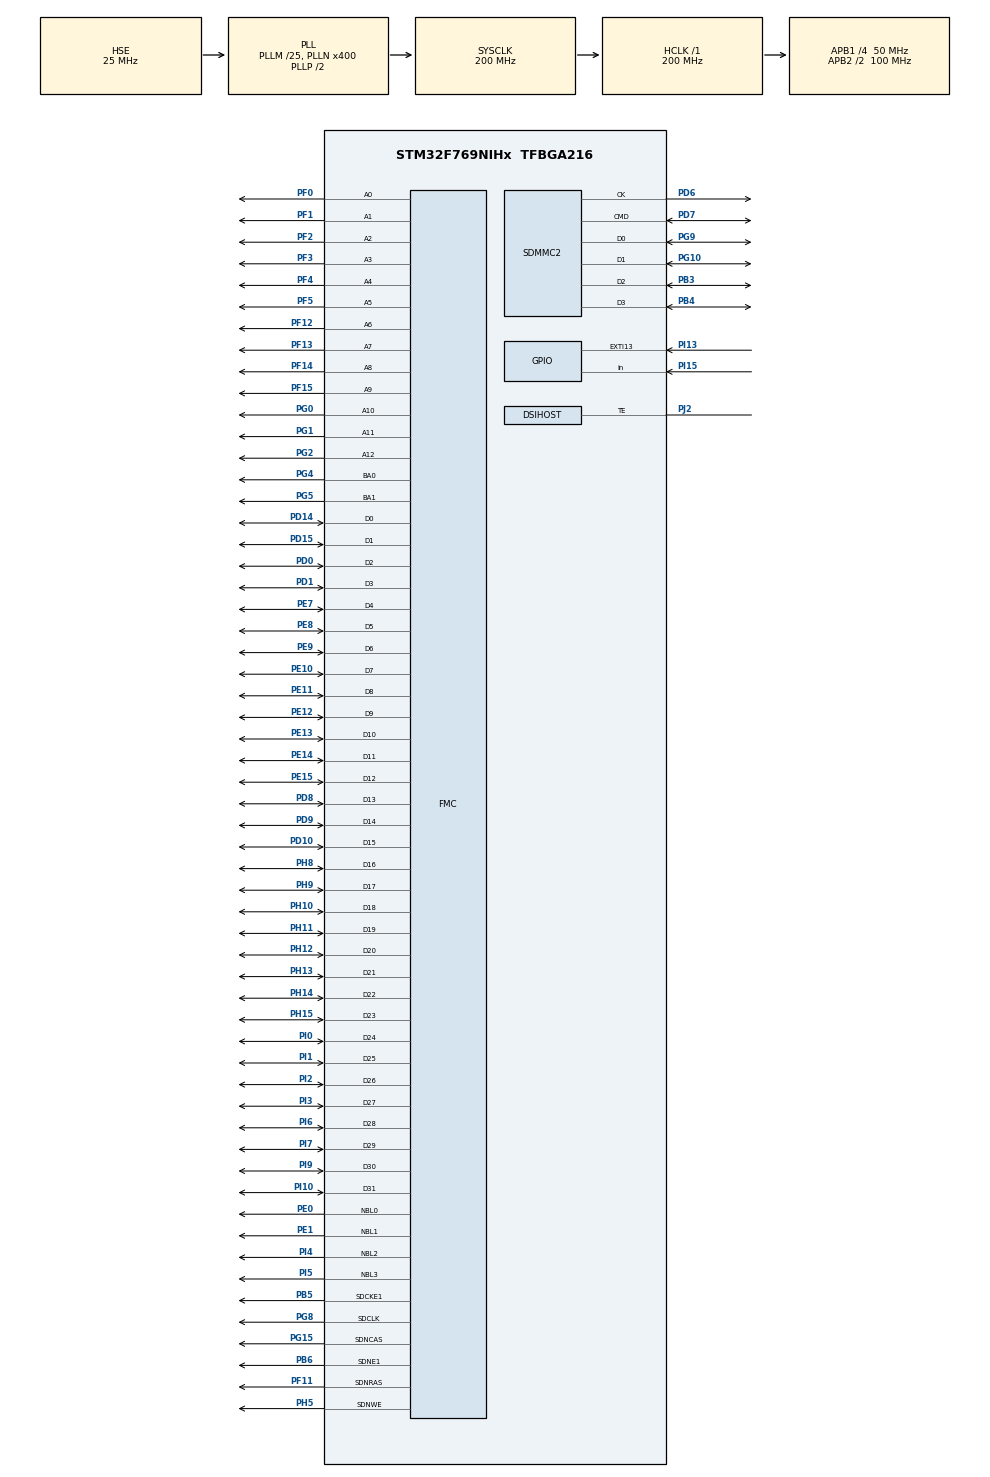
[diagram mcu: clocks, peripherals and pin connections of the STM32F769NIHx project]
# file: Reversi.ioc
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ADC1.Channel-0\#ChannelRegularConversion=ADC_CHANNEL_TEMPSENSOR
ADC1.NbrOfConversionFlag=1
ADC1.Rank-0\#ChannelRegularConversion=1
ADC1.SamplingTime-0\#ChannelRegularConversion=ADC_SAMPLETIME_3CYCLES
ADC1.master=1
CORTEX_M7.CPU_DCache=Enabled
CORTEX_M7.CPU_ICache=Enabled
DSIHOST_CKN.Mode=DSIHost_Adapted_TE
DSIHOST_CKN.Signal=DSIHOST_CKN
DSIHOST_CKP.Mode=DSIHost_Adapted_TE
DSIHOST_CKP.Signal=DSIHOST_CKP
DSIHOST_D0N.Mode=DSIHost_Adapted_TE
DSIHOST_D0N.Signal=DSIHOST_D0N
DSIHOST_D0P.Mode=DSIHost_Adapted_TE
DSIHOST_D0P.Signal=DSIHOST_D0P
DSIHOST_D1N.Mode=DSIHost_Adapted_TE
DSIHOST_D1N.Signal=DSIHOST_D1N
DSIHOST_D1P.Mode=DSIHost_Adapted_TE
DSIHOST_D1P.Signal=DSIHOST_D1P
FATFS.BSP.number=1
FATFS0.BSP.STBoard=false
FATFS0.BSP.api=Unknown
FATFS0.BSP.i2caddr=0
FATFS0.BSP.instance=PI15
FATFS0.BSP.ip=GPIO
FATFS0.BSP.mode=Input
FATFS0.BSP.name=Detect_SDIO
FATFS0.BSP.solution=PI15
Mcu.Family=STM32F7
Mcu.Name=STM32F769NIHx
Mcu.Package=TFBGA216
NVIC.ADC_IRQn=true\:0\:0\:false\:false\:true\:true\:true
NVIC.EXTI15_10_IRQn=true\:0\:0\:false\:false\:true\:true\:true
NVIC.PriorityGroup=NVIC_PRIORITYGROUP_4
NVIC.TIM6_DAC_IRQn=true\:0\:0\:false\:false\:true\:true\:true
NVIC.TIM7_IRQn=true\:0\:0\:false\:false\:true\:true\:true
PB3.Mode=SD_4_bits_Wide_bus
PB3.Signal=SDMMC2_D2
PB4.Mode=SD_4_bits_Wide_bus
PB4.Signal=SDMMC2_D3
PB5.Mode=SdramChipSelect2_1
PB5.Signal=FMC_SDCKE1
PB6.Mode=SdramChipSelect2_1
PB6.Signal=FMC_SDNE1
PD0.Signal=FMC_D2_DA2
PD1.Signal=FMC_D3_DA3
PD10.Signal=FMC_D15_DA15
PD14.Signal=FMC_D0_DA0
PD15.Signal=FMC_D1_DA1
PD6.Mode=SD_4_bits_Wide_bus
PD6.Signal=SDMMC2_CK
PD7.Mode=SD_4_bits_Wide_bus
PD7.Signal=SDMMC2_CMD
PD8.Signal=FMC_D13_DA13
PD9.Signal=FMC_D14_DA14
PE0.Signal=FMC_NBL0
PE1.Signal=FMC_NBL1
PE10.Signal=FMC_D7_DA7
PE11.Signal=FMC_D8_DA8
PE12.Signal=FMC_D9_DA9
PE13.Signal=FMC_D10_DA10
PE14.Signal=FMC_D11_DA11
PE15.Signal=FMC_D12_DA12
PE7.Signal=FMC_D4_DA4
PE8.Signal=FMC_D5_DA5
PE9.Signal=FMC_D6_DA6
PF0.Signal=FMC_A0
PF1.Signal=FMC_A1
PF11.Signal=FMC_SDNRAS
PF12.Signal=FMC_A6
PF13.Signal=FMC_A7
PF14.Signal=FMC_A8
PF15.Signal=FMC_A9
PF2.Signal=FMC_A2
PF3.Signal=FMC_A3
PF4.Signal=FMC_A4
PF5.Signal=FMC_A5
PG0.Signal=FMC_A10
PG1.Signal=FMC_A11
PG10.Mode=SD_4_bits_Wide_bus
PG10.Signal=SDMMC2_D1
PG15.Signal=FMC_SDNCAS
PG2.Signal=FMC_A12
PG4.Signal=FMC_A14_BA0
PG5.Signal=FMC_A15_BA1
PG8.Signal=FMC_SDCLK
PG9.Mode=SD_4_bits_Wide_bus
PG9.Signal=SDMMC2_D0
PH0/OSC_IN.Mode=HSE-External-Oscillator
PH0/OSC_IN.Signal=RCC_OSC_IN
PH1/OSC_OUT.Mode=HSE-External-Oscillator
PH1/OSC_OUT.Signal=RCC_OSC_OUT
PH10.Signal=FMC_D18
PH11.Signal=FMC_D19
PH12.Signal=FMC_D20
PH13.Signal=FMC_D21
PH14.Signal=FMC_D22
PH15.Signal=FMC_D23
PH5.Signal=FMC_SDNWE
PH8.Signal=FMC_D16
PH9.Signal=FMC_D17
PI0.Signal=FMC_D24
PI1.Signal=FMC_D25
PI10.Signal=FMC_D31
PI13.Signal=GPXTI13
PI15.Signal=GPIO_Input
PI2.Signal=FMC_D26
PI3.Signal=FMC_D27
PI4.Signal=FMC_NBL2
PI5.Signal=FMC_NBL3
PI6.Signal=FMC_D28
PI7.Signal=FMC_D29
PI9.Signal=FMC_D30
PJ2.Mode=DSIHost_Adapted_TE
PJ2.Signal=DSIHOST_TE
ProjectManager.HeapSize=0x200
ProjectManager.StackSize=0x400
ProjectManager.TargetToolchain=STM32CubeIDE
RCC.AHBFreq_Value=200000000
RCC.APB1CLKDivider=RCC_HCLK_DIV4
RCC.APB1Freq_Value=50000000
RCC.APB1TimFreq_Value=100000000
RCC.APB2CLKDivider=RCC_HCLK_DIV2
RCC.APB2Freq_Value=100000000
RCC.APB2TimFreq_Value=200000000
RCC.CortexFreq_Value=200000000
RCC.HCLKFreq_Value=200000000
RCC.HSE_VALUE=25000000
RCC.HSI_VALUE=16000000
RCC.LSE_VALUE=32768
RCC.PLLI2SN=96
RCC.PLLM=25
RCC.PLLN=400
RCC.PLLQ=8
RCC.PLLSourceVirtual=RCC_PLLSOURCE_HSE
RCC.SDMMC2ClockSelection=RCC_SDMMC2CLKSOURCE_CLK48
RCC.SYSCLKFreq_VALUE=200000000
RCC.SYSCLKSource=RCC_SYSCLKSOURCE_PLLCLK
RCC.USBFreq_Value=50000000
RCC.VCOOutputFreq_Value=400000000
SH.FMC_A0.0=FMC_A0,13b-sda1
SH.FMC_A1.0=FMC_A1,13b-sda1
SH.FMC_A10.0=FMC_A10,13b-sda1
SH.FMC_A11.0=FMC_A11,13b-sda1
SH.FMC_A12.0=FMC_A12,13b-sda1
SH.FMC_A14_BA0.0=FMC_BA0,FourSdramBanks1
SH.FMC_A15_BA1.0=FMC_BA1,FourSdramBanks1
SH.FMC_A2.0=FMC_A2,13b-sda1
SH.FMC_A3.0=FMC_A3,13b-sda1
SH.FMC_A4.0=FMC_A4,13b-sda1
SH.FMC_A5.0=FMC_A5,13b-sda1
SH.FMC_A6.0=FMC_A6,13b-sda1
SH.FMC_A7.0=FMC_A7,13b-sda1
SH.FMC_A8.0=FMC_A8,13b-sda1
SH.FMC_A9.0=FMC_A9,13b-sda1
SH.FMC_D0_DA0.0=FMC_D0,sd-32b-d1
SH.FMC_D10_DA10.0=FMC_D10,sd-32b-d1
SH.FMC_D11_DA11.0=FMC_D11,sd-32b-d1
SH.FMC_D12_DA12.0=FMC_D12,sd-32b-d1
SH.FMC_D13_DA13.0=FMC_D13,sd-32b-d1
SH.FMC_D14_DA14.0=FMC_D14,sd-32b-d1
SH.FMC_D15_DA15.0=FMC_D15,sd-32b-d1
SH.FMC_D16.0=FMC_D16,sd-32b-d1
SH.FMC_D17.0=FMC_D17,sd-32b-d1
SH.FMC_D18.0=FMC_D18,sd-32b-d1
SH.FMC_D19.0=FMC_D19,sd-32b-d1
SH.FMC_D1_DA1.0=FMC_D1,sd-32b-d1
SH.FMC_D20.0=FMC_D20,sd-32b-d1
SH.FMC_D21.0=FMC_D21,sd-32b-d1
SH.FMC_D22.0=FMC_D22,sd-32b-d1
SH.FMC_D23.0=FMC_D23,sd-32b-d1
SH.FMC_D24.0=FMC_D24,sd-32b-d1
SH.FMC_D25.0=FMC_D25,sd-32b-d1
SH.FMC_D26.0=FMC_D26,sd-32b-d1
SH.FMC_D27.0=FMC_D27,sd-32b-d1
SH.FMC_D28.0=FMC_D28,sd-32b-d1
SH.FMC_D29.0=FMC_D29,sd-32b-d1
SH.FMC_D2_DA2.0=FMC_D2,sd-32b-d1
SH.FMC_D30.0=FMC_D30,sd-32b-d1
SH.FMC_D31.0=FMC_D31,sd-32b-d1
SH.FMC_D3_DA3.0=FMC_D3,sd-32b-d1
SH.FMC_D4_DA4.0=FMC_D4,sd-32b-d1
SH.FMC_D5_DA5.0=FMC_D5,sd-32b-d1
SH.FMC_D6_DA6.0=FMC_D6,sd-32b-d1
SH.FMC_D7_DA7.0=FMC_D7,sd-32b-d1
SH.FMC_D8_DA8.0=FMC_D8,sd-32b-d1
SH.FMC_D9_DA9.0=FMC_D9,sd-32b-d1
SH.FMC_NBL0.0=FMC_NBL0,Sd4ByteEnable1
SH.FMC_NBL1.0=FMC_NBL1,Sd4ByteEnable1
SH.FMC_NBL2.0=FMC_NBL2,Sd4ByteEnable1
SH.FMC_NBL3.0=FMC_NBL3,Sd4ByteEnable1
SH.FMC_SDCLK.0=FMC_SDCLK,13b-sda1
SH.FMC_SDNCAS.0=FMC_SDNCAS,13b-sda1
SH.FMC_SDNRAS.0=FMC_SDNRAS,13b-sda1
SH.FMC_SDNWE.0=FMC_SDNWE,13b-sda1
TIM6.AutoReloadPreload=TIM_AUTORELOAD_PRELOAD_ENABLE
TIM6.Period=14141
TIM6.Prescaler=14141
TIM7.AutoReloadPreload=TIM_AUTORELOAD_PRELOAD_ENABLE
TIM7.Period=9999
TIM7.Prescaler=9999
VP_ADC1_TempSens_Input.Mode=IN-TempSens
VP_DMA2D_VS_DMA2D.Mode=DMA2D_Activate
VP_FATFS_VS_SDIO.Mode=SDIO
VP_LTDC_DSIMode.Mode=RGB888
VP_TIM6_VS_ClockSourceINT.Mode=Enable_Timer
VP_TIM7_VS_ClockSourceINT.Mode=Enable_Timer
board=STM32F769I-DISC1

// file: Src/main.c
/* USER CODE BEGIN Header */
/**
  ******************************************************************************
  * @file           : main.c
  * @brief          : Main program body
  ******************************************************************************
  * @attention
  *
  * <h2><center>&copy; Copyright (c) 2019 STMicroelectronics.
  * All rights reserved.</center></h2>
  *
  * This software component is licensed by ST under BSD 3-Clause license,
  * the "License"; You may not use this file except in compliance with the
  * License. You may obtain a copy of the License at:
  *                        opensource.org/licenses/BSD-3-Clause
  *
  ******************************************************************************
  */
/* USER CODE END Header */

#include "main.h"
#include "fatfs.h"

/* USER CODE BEGIN Includes */
#include "stm32f769i_discovery.h"
#include "stm32f769i_discovery_lcd.h"
#include "stm32f769i_discovery_ts.h"
#include "stdio.h"
#include <stdlib.h>
#include <time.h>
/* USER CODE END Includes */

/* USER CODE BEGIN PD */
#define TEMP_REFRESH_PERIOD   1000    /* Internal temperature refresh period */
#define MAX_CONVERTED_VALUE   4095    /* Max converted value */
#define AMBIENT_TEMP            25    /* Ambient Temperature */
#define VSENS_AT_AMBIENT_TEMP  760    /* VSENSE value (mv) at ambient temperature */
#define AVG_SLOPE               25    /* Avg_Solpe multiply by 10 */
#define VREF                  3300
/* USER CODE END PD */

ADC_HandleTypeDef hadc1;

DMA2D_HandleTypeDef hdma2d;

DSI_HandleTypeDef hdsi;

LTDC_HandleTypeDef hltdc;

SD_HandleTypeDef hsd2;

TIM_HandleTypeDef htim6;
TIM_HandleTypeDef htim7;

SDRAM_HandleTypeDef hsdram1;

/* USER CODE BEGIN PV */

 int flagTemp=0;
TS_StateTypeDef TS_State;
uint32_t ConvertedValue;
long int JTemp;
char desc[100];
char clockTime[20];
char timerString[20];
char timeOutString[20];

int flagTouchScreen=0;
int startSoft=0;
int startARMSoft=0;

int sec=0;
int min=0;
int hour=0;

int turnFlag=0;
int startFlag=0;
int startARMFlag=0;
int flagClock=0;
int downTimer=20;

char board[8][8]={"........",
                  "........",
                  "........",
                  "...xo...",
                  "...ox...",
                  "........",
                  "........",
                  "........"};

char symbPlayer;
char symbAdv;

int newPlayer=0;
int gameON=0;
int gameARMon=0;
int gameEnd=0;
int firstMove=0;

uint16_t casaX=0;
uint16_t casaY=0;
uint16_t jogadaX=0;
uint16_t jogadaY=0;

uint32_t colorP1 =  LCD_COLOR_LIGHTGREEN ;
uint32_t colorP2 =  LCD_COLOR_LIGHTRED ;
uint32_t colorPlayer;
//uint32_t colorAdv;

int timOutFlag=0;
int timOutP1=0;
int timOutP2=0;

int j=0;
int k=0;
int l=0;

int jogPossiveisX[20]={0};
int jogPossiveisY[20]={0};
int indx=0;

/* USER CODE END PV */

void SystemClock_Config(void);
static void MX_GPIO_Init(void);
static void MX_ADC1_Init(void);
static void MX_DMA2D_Init(void);
static void MX_DSIHOST_DSI_Init(void);
static void MX_FMC_Init(void);
static void MX_LTDC_Init(void);
static void MX_SDMMC2_SD_Init(void);
static void MX_TIM6_Init(void);
static void MX_TIM7_Init(void);
/* USER CODE BEGIN PFP */

static void LCD_Config();

static void startGame();

void gameOver();

void playARM();

void playHuman();

void jogadasPossiveis(char symbPlayer, char symbAdv);

void jogada(char symbPlayer, char symbAdv,uint32_t colorPlayer, int casaX, int casaY);

/* USER CODE END PFP */

/* USER CODE BEGIN 0 */

void HAL_GPIO_EXTI_Callback(uint16_t GPIO_Pin){
	if(GPIO_Pin == GPIO_PIN_13){

		BSP_TS_GetState(&TS_State);

		if(TS_State.touchDetected){

			flagTouchScreen=1;
	     }
    }
}

void  HAL_TIM_PeriodElapsedCallback(TIM_HandleTypeDef *htim){
	if(htim->Instance == TIM7){            //1 em 1 seg
			flagClock=1;
		}

	if(htim->Instance == TIM6){           // 2 em 2 seg
		flagTemp=1;
	}

}

/* USER CODE END 0 */

int main(void)
{

  /* Enable I-Cache---------------------------------------------------------*/

	SCB_EnableICache();

  /* Enable D-Cache---------------------------------------------------------*/
  SCB_EnableDCache();

  /* MCU Configuration--------------------------------------------------------*/

  /* Reset of all peripherals, Initializes the Flash interface and the Systick. */
  HAL_Init();

  /* Configure the system clock */
  SystemClock_Config();

  /* Initialize all configured peripherals */
  MX_GPIO_Init();
  MX_ADC1_Init();
  MX_DMA2D_Init();
  MX_DSIHOST_DSI_Init();
  MX_FMC_Init();
  MX_LTDC_Init();
  MX_SDMMC2_SD_Init();
  MX_TIM6_Init();
  MX_TIM7_Init();
  MX_FATFS_Init();
  /* USER CODE BEGIN 2 */
    BSP_LED_Init(LED_RED);
    BSP_PB_Init(BUTTON_WAKEUP, BUTTON_MODE_GPIO);

    LCD_Config();

    BSP_TS_Init(800,480);
    BSP_TS_ITConfig();

    HAL_ADC_Start(&hadc1);     //start do adc

    HAL_TIM_Base_Start_IT(&htim6);
    HAL_TIM_Base_Start_IT(&htim7);

  /* USER CODE END 2 */

  /* Infinite loop */
  while (1)
  {

    /* USER CODE BEGIN 3 */

/*   Clock     */
if(flagClock==1){
  flagClock=0;

  sec++;
  if(sec==60){
	  sec=0;
	  min++;
  }

  if(min==60){
	  min=0;
	  hour++;
  }

  BSP_LCD_SetFont(&Font16);
  BSP_LCD_SetTextColor(LCD_COLOR_BLACK);
  BSP_LCD_SetBackColor(LCD_COLOR_WHITE);
  sprintf(clockTime, "Time: %2d:%2d:%2d", hour,min,sec);
  BSP_LCD_DisplayStringAt(600, 400, (uint8_t *)clockTime, LEFT_MODE);

  //Temporizador de 20 seg
  if(gameON ==1 || gameARMon ==1){
	  downTimer--;
	  sprintf(timerString, "Time Left: %2d s", downTimer);
	  BSP_LCD_DisplayStringAt(550, 300, (uint8_t *)timerString, LEFT_MODE);

	  if (downTimer <= 0){
		turnFlag=1;
		timOutFlag=1;

	  }
  }

}

/* Temperature Sensor */
	  if (flagTemp==1){
		  flagTemp=0;

		  HAL_StatusTypeDef status=HAL_ADC_PollForConversion(&hadc1,TEMP_REFRESH_PERIOD);

		 	  if(status==HAL_OK)
		 	  {
		 		  ConvertedValue=HAL_ADC_GetValue(&hadc1); //get value

		 		  JTemp = ((((ConvertedValue * VREF)/MAX_CONVERTED_VALUE) - VSENS_AT_AMBIENT_TEMP) * 10 / AVG_SLOPE) + AMBIENT_TEMP;
		 		  /* Display the Temperature Value on the LCD */
		 		  sprintf(desc, "T= %ld C", JTemp);
		 		  BSP_LCD_SetTextColor(LCD_COLOR_BLACK);
		 		  BSP_LCD_SetBackColor(LCD_COLOR_WHITE);
		 		  BSP_LCD_SetFont(&Font16);
		 		  BSP_LCD_DisplayStringAt(600, 435, (uint8_t *)desc, LEFT_MODE);
		 	  }
	  }

/*Touch Screen*/

 if (flagTouchScreen==1){
	 flagTouchScreen=0;

	 if( (int)TS_State.touchX[0] <480 && (int)TS_State.touchY[0] <480  ){

		   turnFlag=1;
	}

	   if( (int)TS_State.touchX[0] >500 &&  (int)TS_State.touchX[0] <780 && (int)TS_State.touchY[0] >180 && (int)TS_State.touchY[0] < 230  ){

		   if(startSoft==0  && startARMSoft==0){
			   startFlag=1;
			   startSoft++;

			   BSP_LCD_SetTextColor(LCD_COLOR_DARKBLUE);
			   BSP_LCD_DrawRect(500, 180, 280, 50);
			  }
	   }

	   if( (int)TS_State.touchX[0] >500 &&  (int)TS_State.touchX[0] <780 && (int)TS_State.touchY[0] >100 && (int)TS_State.touchY[0] < 150  ){

				   if(startSoft==0  && startARMSoft==0){
					   startARMFlag=1;
						startARMSoft++;

					BSP_LCD_SetTextColor(LCD_COLOR_DARKBLUE);
					BSP_LCD_DrawRect(500, 100, 280, 50);

				   }
	   }

	   //Reset do Relogio
	   if( (int)TS_State.touchX[0] >500 &&  (int)TS_State.touchX[0] <800 && (int)TS_State.touchY[0] >250 && (int)TS_State.touchY[0] < 400  ){
		   sec=0;
		   min=0;
		   hour=0;

		   	   	   	 BSP_LCD_SetFont(&Font16);
					 BSP_LCD_SetTextColor(LCD_COLOR_BLACK);
					 BSP_LCD_SetBackColor(LCD_COLOR_WHITE);
					 sprintf(clockTime, "Time: %2d:%2d:%2d", hour,min,sec);
					 BSP_LCD_DisplayStringAt(600, 400, (uint8_t *)clockTime, LEFT_MODE);

	   }

 }

/*  PUSH-BUTTON  */
	  if(BSP_PB_GetState(BUTTON_WAKEUP)==1){
		 /*

		  LCD_Config();
		  gameON=0;
		  gameARMon=0;
		  startSoft=0;
		  startARMSoft=0;
		  newPlayer=0;

		  BSP_LCD_SetBackColor(LCD_COLOR_WHITE);

		  downTimer=20;

		 //volta a escrever a matriz inicial
		        for (int i=0;i<8;i++){
		                    for (int j=0;j<8;j++){
		                   board[i][j]='.';
		                  }
		                }
		                board[3][3]='x';
		                board[3][4]='o';
		                board[4][3]='o';
		                board[4][4]='x';

		   */
		  HAL_Delay(75);
		  newPlayer++;
		  downTimer=20;

	  }

/*    Play game against Human     */
if(startFlag==1 ){
	  startFlag=0;

	  gameON=1;
	  startGame();

}

if (gameON==1){

	playHuman();

}

/* Play against ARM   */
if(startARMFlag==1){
	startARMFlag=0;

	 startGame();
	 gameARMon=1;

}

if(gameARMon ==1){
	playARM();

}

/*Game over */

if(gameEnd==1){
	gameEnd=0;

	gameOver();

 }

  }
  /* USER CODE END 3 */
}

void SystemClock_Config(void)
{
  RCC_OscInitTypeDef RCC_OscInitStruct = {0};
  RCC_ClkInitTypeDef RCC_ClkInitStruct = {0};
  RCC_PeriphCLKInitTypeDef PeriphClkInitStruct = {0};

  /** Configure the main internal regulator output voltage
  */
  __HAL_RCC_PWR_CLK_ENABLE();
  __HAL_PWR_VOLTAGESCALING_CONFIG(PWR_REGULATOR_VOLTAGE_SCALE1);
  /** Initializes the CPU, AHB and APB busses clocks
  */
  RCC_OscInitStruct.OscillatorType = RCC_OSCILLATORTYPE_HSE;
  RCC_OscInitStruct.HSEState = RCC_HSE_ON;
  RCC_OscInitStruct.PLL.PLLState = RCC_PLL_ON;
  RCC_OscInitStruct.PLL.PLLSource = RCC_PLLSOURCE_HSE;
  RCC_OscInitStruct.PLL.PLLM = 25;
  RCC_OscInitStruct.PLL.PLLN = 400;
  RCC_OscInitStruct.PLL.PLLP = RCC_PLLP_DIV2;
  RCC_OscInitStruct.PLL.PLLQ = 8;
  if (HAL_RCC_OscConfig(&RCC_OscInitStruct) != HAL_OK)
  {
    Error_Handler();
  }
  /** Activate the Over-Drive mode
  */
  if (HAL_PWREx_EnableOverDrive() != HAL_OK)
  {
    Error_Handler();
  }
  /** Initializes the CPU, AHB and APB busses clocks
  */
  RCC_ClkInitStruct.ClockType = RCC_CLOCKTYPE_HCLK|RCC_CLOCKTYPE_SYSCLK
                              |RCC_CLOCKTYPE_PCLK1|RCC_CLOCKTYPE_PCLK2;
  RCC_ClkInitStruct.SYSCLKSource = RCC_SYSCLKSOURCE_PLLCLK;
  RCC_ClkInitStruct.AHBCLKDivider = RCC_SYSCLK_DIV1;
  RCC_ClkInitStruct.APB1CLKDivider = RCC_HCLK_DIV4;
  RCC_ClkInitStruct.APB2CLKDivider = RCC_HCLK_DIV2;

  if (HAL_RCC_ClockConfig(&RCC_ClkInitStruct, FLASH_LATENCY_6) != HAL_OK)
  {
    Error_Handler();
  }
  PeriphClkInitStruct.PeriphClockSelection = RCC_PERIPHCLK_LTDC|RCC_PERIPHCLK_SDMMC2
                              |RCC_PERIPHCLK_CLK48;
  PeriphClkInitStruct.PLLSAI.PLLSAIN = 192;
  PeriphClkInitStruct.PLLSAI.PLLSAIR = 2;
  PeriphClkInitStruct.PLLSAI.PLLSAIQ = 2;
  PeriphClkInitStruct.PLLSAI.PLLSAIP = RCC_PLLSAIP_DIV2;
  PeriphClkInitStruct.PLLSAIDivQ = 1;
  PeriphClkInitStruct.PLLSAIDivR = RCC_PLLSAIDIVR_2;
  PeriphClkInitStruct.Clk48ClockSelection = RCC_CLK48SOURCE_PLL;
  PeriphClkInitStruct.Sdmmc2ClockSelection = RCC_SDMMC2CLKSOURCE_CLK48;
  if (HAL_RCCEx_PeriphCLKConfig(&PeriphClkInitStruct) != HAL_OK)
  {
    Error_Handler();
  }
}

static void MX_ADC1_Init(void)
{

  ADC_ChannelConfTypeDef sConfig = {0};

  /** Configure the global features of the ADC (Clock, Resolution, Data Alignment and number of conversion)
  */
  hadc1.Instance = ADC1;
  hadc1.Init.ClockPrescaler = ADC_CLOCK_SYNC_PCLK_DIV4;
  hadc1.Init.Resolution = ADC_RESOLUTION_12B;
  hadc1.Init.ScanConvMode = DISABLE;
  hadc1.Init.ContinuousConvMode = DISABLE;
  hadc1.Init.DiscontinuousConvMode = DISABLE;
  hadc1.Init.ExternalTrigConvEdge = ADC_EXTERNALTRIGCONVEDGE_NONE;
  hadc1.Init.ExternalTrigConv = ADC_SOFTWARE_START;
  hadc1.Init.DataAlign = ADC_DATAALIGN_RIGHT;
  hadc1.Init.NbrOfConversion = 1;
  hadc1.Init.DMAContinuousRequests = DISABLE;
  hadc1.Init.EOCSelection = ADC_EOC_SINGLE_CONV;
  if (HAL_ADC_Init(&hadc1) != HAL_OK)
  {
    Error_Handler();
  }
  /** Configure for the selected ADC regular channel its corresponding rank in the sequencer and its sample time.
  */
  sConfig.Channel = ADC_CHANNEL_TEMPSENSOR;
  sConfig.Rank = ADC_REGULAR_RANK_1;
  sConfig.SamplingTime = ADC_SAMPLETIME_3CYCLES;
  if (HAL_ADC_ConfigChannel(&hadc1, &sConfig) != HAL_OK)
  {
    Error_Handler();
  }

}

static void MX_DMA2D_Init(void)
{

  hdma2d.Instance = DMA2D;
  hdma2d.Init.Mode = DMA2D_M2M;
  hdma2d.Init.ColorMode = DMA2D_OUTPUT_ARGB8888;
  hdma2d.Init.OutputOffset = 0;
  hdma2d.LayerCfg[1].InputOffset = 0;
  hdma2d.LayerCfg[1].InputColorMode = DMA2D_INPUT_ARGB8888;
  hdma2d.LayerCfg[1].AlphaMode = DMA2D_NO_MODIF_ALPHA;
  hdma2d.LayerCfg[1].InputAlpha = 0;
  hdma2d.LayerCfg[1].AlphaInverted = DMA2D_REGULAR_ALPHA;
  hdma2d.LayerCfg[1].RedBlueSwap = DMA2D_RB_REGULAR;
  if (HAL_DMA2D_Init(&hdma2d) != HAL_OK)
  {
    Error_Handler();
  }
  if (HAL_DMA2D_ConfigLayer(&hdma2d, 1) != HAL_OK)
  {
    Error_Handler();
  }

}

static void MX_DSIHOST_DSI_Init(void)
{

  DSI_PLLInitTypeDef PLLInit = {0};
  DSI_HOST_TimeoutTypeDef HostTimeouts = {0};
  DSI_PHY_TimerTypeDef PhyTimings = {0};
  DSI_LPCmdTypeDef LPCmd = {0};
  DSI_CmdCfgTypeDef CmdCfg = {0};

  hdsi.Instance = DSI;
  hdsi.Init.AutomaticClockLaneControl = DSI_AUTO_CLK_LANE_CTRL_DISABLE;
  hdsi.Init.TXEscapeCkdiv = 4;
  hdsi.Init.NumberOfLanes = DSI_ONE_DATA_LANE;
  PLLInit.PLLNDIV = 20;
  PLLInit.PLLIDF = DSI_PLL_IN_DIV1;
  PLLInit.PLLODF = DSI_PLL_OUT_DIV1;
  if (HAL_DSI_Init(&hdsi, &PLLInit) != HAL_OK)
  {
    Error_Handler();
  }
  HostTimeouts.TimeoutCkdiv = 1;
  HostTimeouts.HighSpeedTransmissionTimeout = 0;
  HostTimeouts.LowPowerReceptionTimeout = 0;
  HostTimeouts.HighSpeedReadTimeout = 0;
  HostTimeouts.LowPowerReadTimeout = 0;
  HostTimeouts.HighSpeedWriteTimeout = 0;
  HostTimeouts.HighSpeedWritePrespMode = DSI_HS_PM_DISABLE;
  HostTimeouts.LowPowerWriteTimeout = 0;
  HostTimeouts.BTATimeout = 0;
  if (HAL_DSI_ConfigHostTimeouts(&hdsi, &HostTimeouts) != HAL_OK)
  {
    Error_Handler();
  }
  PhyTimings.ClockLaneHS2LPTime = 28;
  PhyTimings.ClockLaneLP2HSTime = 33;
  PhyTimings.DataLaneHS2LPTime = 15;
  PhyTimings.DataLaneLP2HSTime = 25;
  PhyTimings.DataLaneMaxReadTime = 0;
  PhyTimings.StopWaitTime = 0;
  if (HAL_DSI_ConfigPhyTimer(&hdsi, &PhyTimings) != HAL_OK)
  {
    Error_Handler();
  }
  if (HAL_DSI_ConfigFlowControl(&hdsi, DSI_FLOW_CONTROL_BTA) != HAL_OK)
  {
    Error_Handler();
  }
  if (HAL_DSI_SetLowPowerRXFilter(&hdsi, 10000) != HAL_OK)
  {
    Error_Handler();
  }
  if (HAL_DSI_ConfigErrorMonitor(&hdsi, HAL_DSI_ERROR_NONE) != HAL_OK)
  {
    Error_Handler();
  }
  LPCmd.LPGenShortWriteNoP = DSI_LP_GSW0P_DISABLE;
  LPCmd.LPGenShortWriteOneP = DSI_LP_GSW1P_DISABLE;
  LPCmd.LPGenShortWriteTwoP = DSI_LP_GSW2P_DISABLE;
  LPCmd.LPGenShortReadNoP = DSI_LP_GSR0P_DISABLE;
  LPCmd.LPGenShortReadOneP = DSI_LP_GSR1P_DISABLE;
  LPCmd.LPGenShortReadTwoP = DSI_LP_GSR2P_DISABLE;
  LPCmd.LPGenLongWrite = DSI_LP_GLW_DISABLE;
  LPCmd.LPDcsShortWriteNoP = DSI_LP_DSW0P_DISABLE;
  LPCmd.LPDcsShortWriteOneP = DSI_LP_DSW1P_DISABLE;
  LPCmd.LPDcsShortReadNoP = DSI_LP_DSR0P_DISABLE;
  LPCmd.LPDcsLongWrite = DSI_LP_DLW_DISABLE;
  LPCmd.LPMaxReadPacket = DSI_LP_MRDP_DISABLE;
  LPCmd.AcknowledgeRequest = DSI_ACKNOWLEDGE_DISABLE;
  if (HAL_DSI_ConfigCommand(&hdsi, &LPCmd) != HAL_OK)
  {
    Error_Handler();
  }
  CmdCfg.VirtualChannelID = 0;
  CmdCfg.ColorCoding = DSI_RGB888;
  CmdCfg.CommandSize = 640;
  CmdCfg.TearingEffectSource = DSI_TE_EXTERNAL;
  CmdCfg.TearingEffectPolarity = DSI_TE_RISING_EDGE;
  CmdCfg.HSPolarity = DSI_HSYNC_ACTIVE_LOW;
  CmdCfg.VSPolarity = DSI_VSYNC_ACTIVE_LOW;
  CmdCfg.DEPolarity = DSI_DATA_ENABLE_ACTIVE_HIGH;
  CmdCfg.VSyncPol = DSI_VSYNC_FALLING;
  CmdCfg.AutomaticRefresh = DSI_AR_ENABLE;
  CmdCfg.TEAcknowledgeRequest = DSI_TE_ACKNOWLEDGE_DISABLE;
  if (HAL_DSI_ConfigAdaptedCommandMode(&hdsi, &CmdCfg) != HAL_OK)
  {
    Error_Handler();
  }
  if (HAL_DSI_SetGenericVCID(&hdsi, 0) != HAL_OK)
  {
    Error_Handler();
  }

}

static void MX_LTDC_Init(void)
{

  LTDC_LayerCfgTypeDef pLayerCfg = {0};
  LTDC_LayerCfgTypeDef pLayerCfg1 = {0};

  hltdc.Instance = LTDC;
  hltdc.Init.HSPolarity = LTDC_HSPOLARITY_AL;
  hltdc.Init.VSPolarity = LTDC_VSPOLARITY_AL;
  hltdc.Init.DEPolarity = LTDC_DEPOLARITY_AL;
  hltdc.Init.PCPolarity = LTDC_PCPOLARITY_IPC;
  hltdc.Init.HorizontalSync = 7;
  hltdc.Init.VerticalSync = 3;
  hltdc.Init.AccumulatedHBP = 14;
  hltdc.Init.AccumulatedVBP = 5;
  hltdc.Init.AccumulatedActiveW = 654;
  hltdc.Init.AccumulatedActiveH = 485;
  hltdc.Init.TotalWidth = 660;
  hltdc.Init.TotalHeigh = 487;
  hltdc.Init.Backcolor.Blue = 0;
  hltdc.Init.Backcolor.Green = 0;
  hltdc.Init.Backcolor.Red = 0;
  if (HAL_LTDC_Init(&hltdc) != HAL_OK)
  {
    Error_Handler();
  }
  pLayerCfg.WindowX0 = 0;
  pLayerCfg.WindowX1 = 0;
  pLayerCfg.WindowY0 = 0;
  pLayerCfg.WindowY1 = 0;
  pLayerCfg.PixelFormat = LTDC_PIXEL_FORMAT_ARGB8888;
  pLayerCfg.Alpha = 0;
  pLayerCfg.Alpha0 = 0;
  pLayerCfg.BlendingFactor1 = LTDC_BLENDING_FACTOR1_CA;
  pLayerCfg.BlendingFactor2 = LTDC_BLENDING_FACTOR2_CA;
  pLayerCfg.FBStartAdress = 0;
  pLayerCfg.ImageWidth = 0;
  pLayerCfg.ImageHeight = 0;
  pLayerCfg.Backcolor.Blue = 0;
  pLayerCfg.Backcolor.Green = 0;
  pLayerCfg.Backcolor.Red = 0;
  if (HAL_LTDC_ConfigLayer(&hltdc, &pLayerCfg, 0) != HAL_OK)
  {
    Error_Handler();
  }
  pLayerCfg1.WindowX0 = 0;
  pLayerCfg1.WindowX1 = 0;
  pLayerCfg1.WindowY0 = 0;
  pLayerCfg1.WindowY1 = 0;
  pLayerCfg1.PixelFormat = LTDC_PIXEL_FORMAT_ARGB8888;
  pLayerCfg1.Alpha = 0;
  pLayerCfg1.Alpha0 = 0;
  pLayerCfg1.BlendingFactor1 = LTDC_BLENDING_FACTOR1_CA;
  pLayerCfg1.BlendingFactor2 = LTDC_BLENDING_FACTOR2_CA;
  pLayerCfg1.FBStartAdress = 0;
  pLayerCfg1.ImageWidth = 0;
  pLayerCfg1.ImageHeight = 0;
  pLayerCfg1.Backcolor.Blue = 0;
  pLayerCfg1.Backcolor.Green = 0;
  pLayerCfg1.Backcolor.Red = 0;
  if (HAL_LTDC_ConfigLayer(&hltdc, &pLayerCfg1, 1) != HAL_OK)
  {
    Error_Handler();
  }

}

static void MX_SDMMC2_SD_Init(void)
{

  hsd2.Instance = SDMMC2;
  hsd2.Init.ClockEdge = SDMMC_CLOCK_EDGE_RISING;
  hsd2.Init.ClockBypass = SDMMC_CLOCK_BYPASS_DISABLE;
  hsd2.Init.ClockPowerSave = SDMMC_CLOCK_POWER_SAVE_DISABLE;
  hsd2.Init.BusWide = SDMMC_BUS_WIDE_1B;
  hsd2.Init.HardwareFlowControl = SDMMC_HARDWARE_FLOW_CONTROL_DISABLE;
  hsd2.Init.ClockDiv = 0;

}

static void MX_TIM6_Init(void)
{

  TIM_MasterConfigTypeDef sMasterConfig = {0};

  htim6.Instance = TIM6;
  htim6.Init.Prescaler = 14141;
  htim6.Init.CounterMode = TIM_COUNTERMODE_UP;
  htim6.Init.Period = 14141;
  htim6.Init.AutoReloadPreload = TIM_AUTORELOAD_PRELOAD_ENABLE;
  if (HAL_TIM_Base_Init(&htim6) != HAL_OK)
  {
    Error_Handler();
  }
  sMasterConfig.MasterOutputTrigger = TIM_TRGO_RESET;
  sMasterConfig.MasterSlaveMode = TIM_MASTERSLAVEMODE_DISABLE;
  if (HAL_TIMEx_MasterConfigSynchronization(&htim6, &sMasterConfig) != HAL_OK)
  {
    Error_Handler();
  }

}

static void MX_TIM7_Init(void)
{

  TIM_MasterConfigTypeDef sMasterConfig = {0};

  htim7.Instance = TIM7;
  htim7.Init.Prescaler = 9999;
  htim7.Init.CounterMode = TIM_COUNTERMODE_UP;
  htim7.Init.Period = 9999;
  htim7.Init.AutoReloadPreload = TIM_AUTORELOAD_PRELOAD_ENABLE;
  if (HAL_TIM_Base_Init(&htim7) != HAL_OK)
  {
    Error_Handler();
  }
  sMasterConfig.MasterOutputTrigger = TIM_TRGO_RESET;
  sMasterConfig.MasterSlaveMode = TIM_MASTERSLAVEMODE_DISABLE;
  if (HAL_TIMEx_MasterConfigSynchronization(&htim7, &sMasterConfig) != HAL_OK)
  {
    Error_Handler();
  }

}

/* FMC initialization function */
static void MX_FMC_Init(void)
{

  FMC_SDRAM_TimingTypeDef SdramTiming = {0};

  /** Perform the SDRAM1 memory initialization sequence
  */
  hsdram1.Instance = FMC_SDRAM_DEVICE;
  /* hsdram1.Init */
  hsdram1.Init.SDBank = FMC_SDRAM_BANK2;
  hsdram1.Init.ColumnBitsNumber = FMC_SDRAM_COLUMN_BITS_NUM_8;
  hsdram1.Init.RowBitsNumber = FMC_SDRAM_ROW_BITS_NUM_13;
  hsdram1.Init.MemoryDataWidth = FMC_SDRAM_MEM_BUS_WIDTH_32;
  hsdram1.Init.InternalBankNumber = FMC_SDRAM_INTERN_BANKS_NUM_4;
  hsdram1.Init.CASLatency = FMC_SDRAM_CAS_LATENCY_1;
  hsdram1.Init.WriteProtection = FMC_SDRAM_WRITE_PROTECTION_DISABLE;
  hsdram1.Init.SDClockPeriod = FMC_SDRAM_CLOCK_DISABLE;
  hsdram1.Init.ReadBurst = FMC_SDRAM_RBURST_DISABLE;
  hsdram1.Init.ReadPipeDelay = FMC_SDRAM_RPIPE_DELAY_0;
  /* SdramTiming */
  SdramTiming.LoadToActiveDelay = 16;
  SdramTiming.ExitSelfRefreshDelay = 16;
  SdramTiming.SelfRefreshTime = 16;
  SdramTiming.RowCycleDelay = 16;
  SdramTiming.WriteRecoveryTime = 16;
  SdramTiming.RPDelay = 16;
  SdramTiming.RCDDelay = 16;

  if (HAL_SDRAM_Init(&hsdram1, &SdramTiming) != HAL_OK)
  {
    Error_Handler( );
  }

}

static void MX_GPIO_Init(void)
{
  GPIO_InitTypeDef GPIO_InitStruct = {0};

  /* GPIO Ports Clock Enable */
  __HAL_RCC_GPIOE_CLK_ENABLE();
  __HAL_RCC_GPIOB_CLK_ENABLE();
  __HAL_RCC_GPIOD_CLK_ENABLE();
  __HAL_RCC_GPIOG_CLK_ENABLE();
  __HAL_RCC_GPIOI_CLK_ENABLE();
  __HAL_RCC_GPIOF_CLK_ENABLE();
  __HAL_RCC_GPIOH_CLK_ENABLE();
  __HAL_RCC_GPIOJ_CLK_ENABLE();

  /*Configure GPIO pin : PI13 */
  GPIO_InitStruct.Pin = GPIO_PIN_13;
  GPIO_InitStruct.Mode = GPIO_MODE_IT_RISING;
  GPIO_InitStruct.Pull = GPIO_NOPULL;
  HAL_GPIO_Init(GPIOI, &GPIO_InitStruct);

  /*Configure GPIO pin : PI15 */
  GPIO_InitStruct.Pin = GPIO_PIN_15;
  GPIO_InitStruct.Mode = GPIO_MODE_INPUT;
  GPIO_InitStruct.Pull = GPIO_NOPULL;
  HAL_GPIO_Init(GPIOI, &GPIO_InitStruct);

  /* EXTI interrupt init*/
  HAL_NVIC_SetPriority(EXTI15_10_IRQn, 0, 0);
  HAL_NVIC_EnableIRQ(EXTI15_10_IRQn);

}

/* USER CODE BEGIN 4 */
static void LCD_Config(void)
{
 int Xpos=0;
 int Space=60;
 int j=0;

  uint32_t  lcd_status = LCD_OK;

  /* Initialize the LCD */
  lcd_status = BSP_LCD_Init();
  while(lcd_status != LCD_OK);

  BSP_LCD_LayerDefaultInit(0, LCD_FB_START_ADDRESS);

  /* Clear the LCD */
  BSP_LCD_Clear(LCD_COLOR_WHITE);

  /* Set the Board  */
   //Draw vertical lines
  BSP_LCD_SetTextColor(LCD_COLOR_DARKBLUE);

  j=0;
  for(int i=0; i<9; i++){

	  	  BSP_LCD_DrawVLine(Xpos+j, 0, 480 );
	  	  j=j+Space;
  }
  //Draw horizontal lines
    BSP_LCD_SetTextColor(LCD_COLOR_DARKBLUE);

    j=0;
    for(int i=0; i<9; i++){

  	  	  BSP_LCD_DrawHLine(0, j, 480 );
  	  	  j=j+Space;
    }

    /*Game menu*/
    BSP_LCD_SetBackColor(LCD_COLOR_LIGHTBLUE);
    BSP_LCD_SetTextColor(LCD_COLOR_LIGHTBLUE);
    BSP_LCD_FillRect(490, 0, 300, 60);
    BSP_LCD_DrawRect(490, 0, 300, 470);

    BSP_LCD_SetTextColor(LCD_COLOR_WHITE);
      BSP_LCD_SetFont(&Font24);
      BSP_LCD_DisplayStringAt(580, 15, (uint8_t *)"REVERSI", LEFT_MODE);

      /*Start button*/

      BSP_LCD_SetBackColor(LCD_COLOR_GREEN);
      BSP_LCD_SetTextColor(LCD_COLOR_GREEN);
      BSP_LCD_FillRect(500, 100, 280, 50);
      BSP_LCD_FillRect(500, 180, 280, 50);

      BSP_LCD_SetTextColor(LCD_COLOR_WHITE);
       BSP_LCD_SetFont(&Font24);
       BSP_LCD_DisplayStringAt(595, 115, (uint8_t *)"Play ARM", LEFT_MODE);
       BSP_LCD_DisplayStringAt(595, 195, (uint8_t *)"Play Human", LEFT_MODE);

}

static void startGame(){
    int Xpos=0;
    int Space=60;
	int j=0;

	BSP_LCD_SetTextColor(LCD_COLOR_LIGHTGRAY);
	BSP_LCD_FillRect(0, 0, 480, 480);

	/* Set the Board  */
	   //Draw vertical lines
	  BSP_LCD_SetTextColor(LCD_COLOR_DARKBLUE);

	  j=0;
	  for(int i=0; i<9; i++){

		  	  BSP_LCD_DrawVLine(Xpos+j, 0, 480 );
		  	  j=j+Space;
	  }
	  //Draw horizontal lines
	    BSP_LCD_SetTextColor(LCD_COLOR_DARKBLUE);

	    j=0;
	    for(int i=0; i<9; i++){

	  	  	  BSP_LCD_DrawHLine(0, j, 480 );
	  	  	  j=j+Space;
	    }

	/*Draw initial symbols*/

		 BSP_LCD_SetTextColor(LCD_COLOR_LIGHTRED);
		 BSP_LCD_FillCircle(210,270,25);
		 BSP_LCD_FillCircle(270,210,25);

		  BSP_LCD_SetTextColor(LCD_COLOR_LIGHTGREEN);
		  BSP_LCD_FillCircle(210,210,25);
		  BSP_LCD_FillCircle(270,270,25);

    /*Draw window for communication */
		  BSP_LCD_SetTextColor(LCD_COLOR_LIGHTGRAY);
		  BSP_LCD_FillRect(500, 280, 281, 100);

}

void gameOver(){
unsigned int nBytes;

int cnt_x =0;
int cnt_o=0;

char score_x[20];
char score_o[20];

//conta o numero de peças dos jogadores
 for (int i=0; i<8; i++){
    for (int j=0; j<8; j++){
         if (board[i][j]=='x'){
             cnt_x++;
        	  }
         if (board[i][j]=='o'){
        	  cnt_o++;
        	  }
   }
 }

 if(cnt_x > cnt_o){
	 BSP_LCD_SetTextColor(LCD_COLOR_BLACK);
	 BSP_LCD_SetFont(&Font24);
	 BSP_LCD_DisplayStringAt(520, 115, (uint8_t *)"PLAYER 1 WINS" , LEFT_MODE);
 }

 else if(cnt_x < cnt_o){
	 BSP_LCD_SetTextColor(LCD_COLOR_BLACK);
	 BSP_LCD_SetFont(&Font24);
	 BSP_LCD_DisplayStringAt(520, 115, (uint8_t *)"PLAYER 2 WINS" , LEFT_MODE);
 }

 if(cnt_x == cnt_o){
	 BSP_LCD_SetTextColor(LCD_COLOR_BLACK);
	 BSP_LCD_SetFont(&Font24);
	 BSP_LCD_DisplayStringAt(520, 115, (uint8_t *)"IT'S A TIE" , LEFT_MODE);
 }

//desenha os menus
     BSP_LCD_SetTextColor(LCD_COLOR_DARKBLUE);
     BSP_LCD_FillRect(0, 0, 800, 60);
     BSP_LCD_FillRect(0, 180, 800, 120);

     BSP_LCD_SetBackColor(LCD_COLOR_DARKBLUE);
     BSP_LCD_SetTextColor(LCD_COLOR_WHITE);
     BSP_LCD_SetFont(&Font24);
     BSP_LCD_DisplayStringAt(0, 15, (uint8_t *)"GAME OVER", CENTER_MODE);

     BSP_LCD_SetTextColor(LCD_COLOR_WHITE);
      BSP_LCD_SetFont(&Font24);
      BSP_LCD_DisplayStringAt(0, 185, (uint8_t *)"SCORE", CENTER_MODE);

      sprintf(score_x, "Player 1: %d", cnt_x);
      BSP_LCD_DisplayStringAt(0, 215, (uint8_t *)score_x, CENTER_MODE);
      sprintf(score_o, "Player 2: %d", cnt_o);
      BSP_LCD_DisplayStringAt(0, 235, (uint8_t *)score_o, CENTER_MODE);

//volta a escrever a matriz
      for (int i=0;i<8;i++){
                  for (int j=0;j<8;j++){
                 board[i][j]='.';
                }
              }
              board[3][3]='x';
              board[3][4]='o';
              board[4][3]='o';
              board[4][4]='x';

//Escreve p cartao SD

if(f_mount(&SDFatFS,SDPath,0)!=FR_OK)
       Error_Handler();

if(f_open(&SDFile,"score.txt",FA_WRITE | FA_CREATE_ALWAYS)!=FR_OK)
       Error_Handler();

 if(f_write(&SDFile, score_x, strlen(score_x), &nBytes)!=FR_OK)
    	Error_Handler();

 if(f_write(&SDFile, score_o, strlen(score_o), &nBytes)!=FR_OK)
    	Error_Handler();

 f_close (&SDFile);

}

void playARM(){

//Player1

	if(newPlayer%2 == 0){

		  	 BSP_LCD_SetTextColor(colorP1);
		  	 BSP_LCD_DisplayStringAt(590, 250, (uint8_t *)"PLAYER 1", LEFT_MODE);

		  	 symbPlayer='x';
		  	 symbAdv='o';
		  	 colorPlayer=colorP1;
		  	 //colorAdv=colorP2;

		  	if(turnFlag==1){
		  		downTimer=20;
		    }

		  	 if(timOutFlag == 1){
		  		timOutFlag=0;
		  		timOutP1++;

		  		sprintf(timeOutString, "Timeout P1: %d", timOutP1);
		  		BSP_LCD_DisplayStringAt(550, 320, (uint8_t *)timeOutString, LEFT_MODE);
		  	 }

		  	 if(timOutP1 == 3){
		  		gameARMon = 0;
		  		gameEnd=1;
		  	 }

		  	 //--Jogada do Player-----------------------------------------------------------
		  	 //------verificar se ha jogadas possiveis------------------------------------------------------------------

					  jogadasPossiveis(symbPlayer, symbAdv);

					  /*se n houver jogadas possiveis a segunda posiçao da matriz (jogPosssiveis[1]) vai estar igual a zero*/
					  /*e preciso verificar a segunda posiçao e nao a primeira pq (0,0) e uma jogada possivel              */

					  if( jogPossiveisX[1]==jogPossiveisY[1]  && jogPossiveisX[1]==0  ){
						  gameARMon = 0;
						  gameEnd = 1;
					  }

		  	 casaX = (int)TS_State.touchX[0]/60;
		  	 casaY = (int)TS_State.touchY[0]/60;

		  	jogada(symbPlayer, symbAdv, colorPlayer, casaX, casaY);
		  }

//Player ARM

		 else{

			newPlayer++;         //qd e o ARM a jogar tenho q incrementar a variavel

		  	BSP_LCD_SetTextColor(colorP2);
		  	 BSP_LCD_DisplayStringAt(590, 250, (uint8_t *)"   ARM   ", LEFT_MODE);

		  	 HAL_Delay(850);  //Delay p q se consiga ler a mensagem "ARM"

		  	symbPlayer='o';
		    symbAdv='x';
		    colorPlayer=colorP2;

		    if(turnFlag==1){
		    	downTimer=20;
		    }

		    if(timOutFlag == 1){
		       timOutFlag=0;
	    		timOutP2++;
		    }

		    if(timOutP2 == 3){
		  		gameARMon = 0;
		  		gameEnd=1;
		    }

		    //--Jogada do ARM---------------------------

		    //------verificar se ha jogadas possiveis------------------------------------------------------------------

		    	  jogadasPossiveis(symbPlayer, symbAdv);

		    	  /*se n houver jogadas possiveis a segunda posiçao da matriz (jogPosssiveis[1]) vai estar igual a zero*/
		    	  /*e preciso verificar a segunda posiçao e nao a primeira pq (0,0) e uma jogada possivel              */

		    	  if( jogPossiveisX[1]==jogPossiveisY[1]  && jogPossiveisX[1]==0  ){
		    		  gameARMon = 0;
		    		  gameEnd = 1;
		    	  }

		    srand(time(NULL));

		    int random_number = rand() %indx;

		    casaX = jogPossiveisX[random_number];
		    casaY = jogPossiveisY[random_number];

		    jogada(symbPlayer, symbAdv, colorPlayer, casaX, casaY);

	 }

   if(turnFlag==1 ){
		 turnFlag=0;
		   newPlayer++;
       }

}

void playHuman(){

	//Player1

		  if(newPlayer%2 == 0){

		  	 BSP_LCD_SetTextColor(colorP1);
		  	 BSP_LCD_DisplayStringAt(590, 250, (uint8_t *)"PLAYER 1", LEFT_MODE);

		  	 symbPlayer='x';
		  	 symbAdv='o';
		  	 colorPlayer=colorP1;

		  	 if(turnFlag==1){
		  		 downTimer=20;
		  	 }

		  	 if(timOutFlag == 1){
		  		timOutFlag=0;
		  		timOutP1++;

		  		sprintf(timeOutString, "Timeout P1: %d", timOutP1);
		  		BSP_LCD_DisplayStringAt(550, 320, (uint8_t *)timeOutString, LEFT_MODE);

		  	 }

		  	 if(timOutP1 == 3){
		  		gameON = 0;
		  		gameEnd=1;
		  	 }

		    }

	//Player2

		 else{

				BSP_LCD_SetTextColor(colorP2);
				 BSP_LCD_DisplayStringAt(590, 250, (uint8_t *)"PLAYER 2", LEFT_MODE);

				symbPlayer='o';
				symbAdv='x';
				colorPlayer=colorP2;

				if(turnFlag==1){
					downTimer=20;
				}

				if(timOutFlag == 1){
				   timOutFlag=0;
					timOutP2++;

					sprintf(timeOutString, "Timeout P2: %d", timOutP2);
					BSP_LCD_DisplayStringAt(550, 340, (uint8_t *)timeOutString, LEFT_MODE);
				}

				if(timOutP2 == 3){
					gameON = 0;
					gameEnd = 1;
				}

		   }

	//------verificar se ha jogadas possiveis------------------------------------------------------------------

		  jogadasPossiveis(symbPlayer, symbAdv);

		  /*se n houver jogadas possiveis a segunda posiçao da matriz (jogPosssiveis[1]) vai estar igual a zero*/
		  /*e preciso verificar a segunda posiçao e nao a primeira pq (0,0) e uma jogada possivel              */

		  if( jogPossiveisX[1]==jogPossiveisY[1]  && jogPossiveisX[1]==0  ){
			  gameON = 0;
			  gameEnd = 1;
		  }

	//----colocar as peças-------------------------------------------------------------------------------------
		  /*para prevenir q o jogador jogue numa casa q e invalida para si mas valida p o jogador seguinte*/
		  /*casa X e casaY so tem valores se tiver sido carregado no ecra*/

		  if(turnFlag==1){
			  casaX = (int)TS_State.touchX[0]/60;
			  casaY = (int)TS_State.touchY[0]/60;
		  }

		  jogada(symbPlayer, symbAdv, colorPlayer, casaX, casaY);

	//----mudar a vez-------------------------------------------------------------------------------------------
		  if(turnFlag==1){
		  		turnFlag=0;
		  	    newPlayer++;

		  	}

}

void jogadasPossiveis(char symbPlayer, char symbAdv){

	//reinicia as matrizes de jogadas possiveis
	for(int i=0; i<21; i++){
		jogPossiveisX[i]=0;
		jogPossiveisY[i]=jogPossiveisX[i];
	}

    indx=0;
	for(casaX=0; casaX<8; casaX++){

			casaY=0;
			while(casaY<8){

				//verificar q a casa está vazia
				if(board[casaY][casaX] == '.'  ){

						//verificar se existe peça adversaria na casa adjacente
						//verifica linha-----------------------------------------------------------------------------

						 if( board[casaY+1][casaX]==symbAdv ){
							 for (int i = casaY ; i<8 ; i++){
							   if( board [i][casaX] == symbPlayer){
									 jogPossiveisX[indx]=casaX;
									 jogPossiveisY[indx]=casaY;
									 indx++;
							   }
							 }
						}
						else if(board[casaY-1][casaX]==symbAdv ){
							for (int i = casaY ; i>0 ; i--){
								if( board [i][casaX] == symbPlayer){
									  jogPossiveisX[indx]=casaX;
									  jogPossiveisY[indx]=casaY;
									  indx++;
								}
							}
						}

					//verfica coluna-----------------------------------------------------------------------

						if( board[casaY][casaX+1] == symbAdv ){
							for (int i = casaX ; i<8 ; i++){
							  if( board [casaY][i] == symbPlayer){
									  jogPossiveisX[indx]=casaX;
									  jogPossiveisY[indx]=casaY;
									  indx++;
							  }
							}
						 }
						else if(  board[casaY][casaX-1]==symbAdv ){
							for (int i = casaX ; i>0 ; i--){
								if( board [casaY][i] == symbPlayer){
									jogPossiveisX[indx]=casaX;
									jogPossiveisY[indx]=casaY;
									indx++;
								}
							}
						}

					//verfica diagonal-----------------------------------------------------------------------
					//---diagonal Norte-esquerda

						  if( board[casaY-1][casaX-1]==symbAdv ){
							  for (int i = casaY, j=casaX ; i>0 ; i--,j--){
								 if( board [i][j] == symbPlayer){
									 jogPossiveisX[indx]=casaX;
									jogPossiveisY[indx]=casaY;
									indx++;
								  }
							  }
						  }

					//---diagonal Norte-direita
						  else if( board[casaY-1][casaX+1]==symbAdv ){
							  for (int i = casaY, j=casaX ; i>0 ; i--,j++){
								 if( board [i][j] == symbPlayer){
									 jogPossiveisX[indx]=casaX;
									jogPossiveisY[indx]=casaY;
									indx++;
								  }
							  }
						  }

				  //---diagonal Sul-esquerda

						  if( board[casaY+1][casaX-1]==symbAdv ){
							  for (int i = casaY, j=casaX ; i<8 ; i++,j--){
								 if( board [i][j] == symbPlayer){
									 jogPossiveisX[indx]=casaX;
									jogPossiveisY[indx]=casaY;
									indx++;
								  }
							  }
						  }

				  //---diagonal Sul-direita

				  else if( board[casaY+1][casaX+1]==symbAdv ){
					  for (int i = casaY, j=casaX ; i<8 ; i++,j++){
						 if( board [i][j] == symbPlayer){
							 jogPossiveisX[indx]=casaX;
							jogPossiveisY[indx]=casaY;
							indx++;
						 }
					  }
				  }
			  }

		 casaY++;
		}
	   }

}

void jogada(char symbPlayer, char symbAdv,uint32_t colorPlayer, int casaX, int casaY){

	  	  jogadaX = casaX*60+30;
		  jogadaY = casaY*60+30;

		  BSP_LCD_SetTextColor(colorPlayer);

		  //verificar q a casa está vazia
		  if(board[casaY][casaX] == '.'  ){

			  //verificar se existe peça adversaria na casa adjacente
			  //verfica linha-----------------------------------------------------------------------------

				  if( board[casaY+1][casaX]==symbAdv ){

					  //troca as peças
					  for (int i = casaY ; i<8 ; i++){
					  	 if( board [i][casaX] == symbPlayer){
					  		  j=i;
					  		  for(int i = casaY; i<=j; i++){
					  			 board[i][casaX]= symbPlayer;

					  			  BSP_LCD_FillCircle(jogadaX,  (i*60+30)  ,25);
					  			  }
					  		  BSP_LCD_FillCircle(jogadaX,jogadaY,25);
					  		  board[casaY][casaX]=symbPlayer;
					  		  }
					  }

				  }
				  else if(board[casaY-1][casaX]==symbAdv ){

				  				 //troca as peças
				  				for (int i = casaY ; i>0 ; i--){
				  				      if( board [i][casaX] == symbPlayer){
				  						  j=i;
				  						 for(int i = casaY; i>=j; i--){
				  						  board[i][casaX]= symbPlayer;

				  						  BSP_LCD_FillCircle(jogadaX,  (i*60+30)  ,25);

				  						  }

				  						BSP_LCD_FillCircle(jogadaX,jogadaY,25);
				  						board[casaY][casaX]=symbPlayer;
				  					  }
				  				 }

				  }

			  //verfica coluna-----------------------------------------------------------------------

				  if( board[casaY][casaX+1] == symbAdv ){

					  //troca as peças
					 for (int i = casaX ; i<8 ; i++){
						 if( board [casaY][i] == symbPlayer){
						  j=i;
						  for(int i = casaX; i<=j; i++){
							 board[casaY][i]= symbPlayer;

							BSP_LCD_FillCircle((i*60+30),  jogadaY  ,25);
							}

						  BSP_LCD_FillCircle(jogadaX,jogadaY,25);
						  board[casaY][casaX]=symbPlayer;
						  }
			        }

				  }
				  else if(  board[casaY][casaX-1]==symbAdv ){

				  				//troca as peças
				  				for (int i = casaX ; i>0 ; i--){
				  				    if( board [casaY][i] == symbPlayer){
				  					 j=i;
				  					 for(int i = casaX; i>=j; i--){
				  						 board[casaY][i]= symbPlayer;

				  					      BSP_LCD_FillCircle((i*60+30),  jogadaY  ,25);

				  						 }
				  					 }
				  				  BSP_LCD_FillCircle(jogadaX,jogadaY,25);
				  				  board[casaY][casaX]=symbPlayer;
				  				 }

					  }

				  //verfica diagonal-----------------------------------------------------------------------
				  //---diagonal Norte-esquerda

				  if( board[casaY-1][casaX-1]==symbAdv ){

					  //procura uma peça do jogador p "entalar"
					  for (int i = casaY, j=casaX ; i>0 ; i--,j--){
						 if( board [i][j] == symbPlayer){

							 //troca as peças
							 k=i;
							 for (int i = casaY, j=casaX ; i>k ; i--,j--){
								 board[i][j]= symbPlayer;
								 BSP_LCD_FillCircle((j*60+30), (i*60+30)  ,25);
							 }

						  BSP_LCD_FillCircle(jogadaX,jogadaY,25);
						  board[casaY][casaX]=symbPlayer;
						  }
					  }
				  }

				  //---diagonal Norte-direita

				 if( board[casaY-1][casaX+1]==symbAdv ){

					  //procura uma peça do jogador p "entalar"
					  for (int i = casaY, j=casaX ; i>0 ; i--,j++){
						 if( board [i][j] == symbPlayer){

							 //troca as peças

							 for (int a = casaY, b=casaX ; a>i ; a--,b++){
								 board[a][b]= symbPlayer;
								 BSP_LCD_FillCircle((b*60+30), (a*60+30)  ,25);

							 }

						  board[casaY][casaX]=symbPlayer;
						  BSP_LCD_FillCircle(jogadaX,jogadaY,25);
						  }
					  }
				  }

				  //---diagonal Sul-esquerda

				  if( board[casaY+1][casaX-1]==symbAdv ){

					  //procura uma peça do jogador p "entalar"
					  for (int i = casaY, j=casaX ; i<8 ; i++,j--){
						 if( board [i][j] == symbPlayer){

							 //troca as peças
							 for (int a = casaY, b=casaX ; a<i ; a++,b--){
							 board[a][b]= symbPlayer;
							 BSP_LCD_FillCircle((b*60+30), (a*60+30)  ,25);

							 }

						  BSP_LCD_FillCircle(jogadaX,jogadaY,25);
						  board[casaY][casaX]=symbPlayer;
						  }
					  }
				  }

				  //---diagonal Sul-direita

				  if( board[casaY+1][casaX+1]==symbAdv ){

					  //procura uma peça do jogador p "entalar"
					  for (int i = casaY, j=casaX ; i<8 ; i++,j++){
						 if( board [i][j] == symbPlayer){

							 //troca as peças
							 k=i;

							 for (int i = casaY, j=casaX ; i<k ; i++,j++){
								 board[i][j]= symbPlayer;
								 BSP_LCD_FillCircle((j*60+30), (i*60+30)  ,25);

							 }

						  BSP_LCD_FillCircle(jogadaX,jogadaY,25);
						  board[casaY][casaX]=symbPlayer;
						  }
					  }
				  }

		}

}

/* USER CODE END 4 */

void Error_Handler(void)
{
  /* USER CODE BEGIN Error_Handler_Debug */
  /* User can add his own implementation to report the HAL error return state */

 BSP_LED_On(LED_RED);

  /* USER CODE END Error_Handler_Debug */
}

/************************ (C) COPYRIGHT STMicroelectronics *****END OF FILE****/
